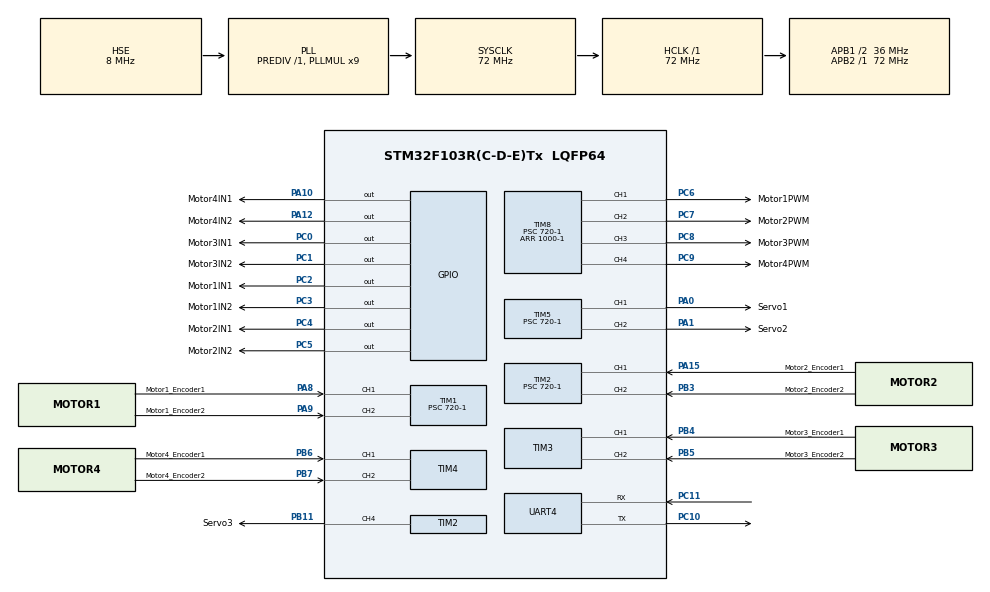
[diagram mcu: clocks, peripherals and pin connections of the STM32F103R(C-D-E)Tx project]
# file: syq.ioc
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Mcu.Family=STM32F1
Mcu.Name=STM32F103R(C-D-E)Tx
Mcu.Package=LQFP64
NVIC.PriorityGroup=NVIC_PRIORITYGROUP_4
NVIC.TIM8_UP_IRQn=true\:0\:0\:false\:false\:true\:true\:true\:true
PA0-WKUP.GPIO_Label=Servo1
PA0-WKUP.Signal=S_TIM5_CH1
PA1.GPIO_Label=Servo2
PA1.Signal=S_TIM5_CH2
PA10.GPIO_Label=Motor4IN1
PA10.Signal=GPIO_Output
PA12.GPIO_Label=Motor4IN2
PA12.Signal=GPIO_Output
PA13.Mode=Serial_Wire
PA13.Signal=SYS_JTMS-SWDIO
PA14.Mode=Serial_Wire
PA14.Signal=SYS_JTCK-SWCLK
PA15.GPIO_Label=Motor2_Encoder1
PA15.Signal=S_TIM2_CH1_ETR
PA8.GPIO_Label=Motor1_Encoder1
PA8.Signal=S_TIM1_CH1
PA9.GPIO_Label=Motor1_Encoder2
PA9.Signal=S_TIM1_CH2
PB11.GPIO_Label=Servo3
PB11.Signal=S_TIM2_CH4
PB3.GPIO_Label=Motor2_Encoder2
PB3.Signal=S_TIM2_CH2
PB4.GPIO_Label=Motor3_Encoder1
PB4.Signal=S_TIM3_CH1
PB5.GPIO_Label=Motor3_Encoder2
PB5.Signal=S_TIM3_CH2
PB6.GPIO_Label=Motor4_Encoder1
PB6.Signal=S_TIM4_CH1
PB7.GPIO_Label=Motor4_Encoder2
PB7.Signal=S_TIM4_CH2
PC0.GPIO_Label=Motor3IN1
PC0.Signal=GPIO_Output
PC1.GPIO_Label=Motor3IN2
PC1.Signal=GPIO_Output
PC10.Mode=Asynchronous
PC10.Signal=UART4_TX
PC11.Mode=Asynchronous
PC11.Signal=UART4_RX
PC2.GPIO_Label=Motor1IN1
PC2.Signal=GPIO_Output
PC3.GPIO_Label=Motor1IN2
PC3.Signal=GPIO_Output
PC4.GPIO_Label=Motor2IN1
PC4.Signal=GPIO_Output
PC5.GPIO_Label=Motor2IN2
PC5.Signal=GPIO_Output
PC6.GPIO_Label=Motor1PWM
PC6.Signal=S_TIM8_CH1
PC7.GPIO_Label=Motor2PWM
PC7.Signal=S_TIM8_CH2
PC8.GPIO_Label=Motor3PWM
PC8.Signal=S_TIM8_CH3
PC9.GPIO_Label=Motor4PWM
PC9.Signal=S_TIM8_CH4
PD0-OSC_IN.Mode=HSE-External-Oscillator
PD0-OSC_IN.Signal=RCC_OSC_IN
PD1-OSC_OUT.Mode=HSE-External-Oscillator
PD1-OSC_OUT.Signal=RCC_OSC_OUT
ProjectManager.HeapSize=0x200
ProjectManager.StackSize=0x400
ProjectManager.TargetToolchain=MDK-ARM V5.32
RCC.AHBFreq_Value=72000000
RCC.APB1CLKDivider=RCC_HCLK_DIV2
RCC.APB1Freq_Value=36000000
RCC.APB1TimFreq_Value=72000000
RCC.APB2Freq_Value=72000000
RCC.APB2TimFreq_Value=72000000
RCC.HCLKFreq_Value=72000000
RCC.PLLMUL=RCC_PLL_MUL9
RCC.PLLSourceVirtual=RCC_PLLSOURCE_HSE
RCC.SYSCLKFreq_VALUE=72000000
RCC.SYSCLKSource=RCC_SYSCLKSOURCE_PLLCLK
RCC.USBFreq_Value=72000000
SH.S_TIM1_CH1.0=TIM1_CH1,Encoder_Interface
SH.S_TIM1_CH2.0=TIM1_CH2,Encoder_Interface
SH.S_TIM2_CH1_ETR.0=TIM2_CH1,Encoder_Interface
SH.S_TIM2_CH2.0=TIM2_CH2,Encoder_Interface
SH.S_TIM2_CH4.0=TIM2_CH4,PWM Generation4 CH4
SH.S_TIM3_CH1.0=TIM3_CH1,Encoder_Interface
SH.S_TIM3_CH2.0=TIM3_CH2,Encoder_Interface
SH.S_TIM4_CH1.0=TIM4_CH1,Encoder_Interface
SH.S_TIM4_CH2.0=TIM4_CH2,Encoder_Interface
SH.S_TIM5_CH1.0=TIM5_CH1,PWM Generation1 CH1
SH.S_TIM5_CH2.0=TIM5_CH2,PWM Generation2 CH2
SH.S_TIM8_CH1.0=TIM8_CH1,PWM Generation1 CH1
SH.S_TIM8_CH2.0=TIM8_CH2,PWM Generation2 CH2
SH.S_TIM8_CH3.0=TIM8_CH3,PWM Generation3 CH3
SH.S_TIM8_CH4.0=TIM8_CH4,PWM Generation4 CH4
TIM1.EncoderMode=TIM_ENCODERMODE_TI12
TIM1.IC1Filter=15
TIM1.IC2Filter=15
TIM1.Period=100-1
TIM1.Prescaler=720-1
TIM2.Channel-PWM\ Generation4\ CH4=TIM_CHANNEL_4
TIM2.EncoderMode=TIM_ENCODERMODE_TI12
TIM2.Period=2000-1
TIM2.Prescaler=720-1
TIM3.EncoderMode=TIM_ENCODERMODE_TI12
TIM4.EncoderMode=TIM_ENCODERMODE_TI12
TIM5.Channel-PWM\ Generation1\ CH1=TIM_CHANNEL_1
TIM5.Channel-PWM\ Generation2\ CH2=TIM_CHANNEL_2
TIM5.Period=2000-1
TIM5.Prescaler=720-1
TIM8.Channel-PWM\ Generation1\ CH1=TIM_CHANNEL_1
TIM8.Channel-PWM\ Generation2\ CH2=TIM_CHANNEL_2
TIM8.Channel-PWM\ Generation3\ CH3=TIM_CHANNEL_3
TIM8.Channel-PWM\ Generation4\ CH4=TIM_CHANNEL_4
TIM8.Period=1000-1
TIM8.Prescaler=720-1
UART4.VirtualMode=Asynchronous
VP_TIM5_VS_ClockSourceINT.Mode=Internal
board=custom

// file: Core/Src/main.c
/* USER CODE BEGIN Header */
/**
  ******************************************************************************
  * @file           : main.c
  * @brief          : Main program body
  ******************************************************************************
  * @attention
  *
  * Copyright (c) 2025 STMicroelectronics.
  * All rights reserved.
  *
  * This software is licensed under terms that can be found in the LICENSE file
  * in the root directory of this software component.
  * If no LICENSE file comes with this software, it is provided AS-IS.
  *
  ******************************************************************************
  */
/* USER CODE END Header */
#include "main.h"
#include "tim.h"
#include "usart.h"
#include "gpio.h"

void SystemClock_Config(void);

int main(void)
{

  /* MCU Configuration--------------------------------------------------------*/

  /* Reset of all peripherals, Initializes the Flash interface and the Systick. */
  HAL_Init();

  /* Configure the system clock */
  SystemClock_Config();

  /* Initialize all configured peripherals */
  MX_GPIO_Init();
  MX_TIM1_Init();
  MX_TIM2_Init();
  MX_TIM3_Init();
  MX_TIM4_Init();
  MX_TIM8_Init();
  MX_TIM5_Init();
  MX_UART4_Init();
  /* USER CODE BEGIN 2 */
	HAL_TIM_Encoder_Start(&htim1,TIM_CHANNEL_ALL);
	HAL_TIM_Encoder_Start(&htim2,TIM_CHANNEL_ALL);
	HAL_TIM_Encoder_Start(&htim3,TIM_CHANNEL_ALL);
	HAL_TIM_Encoder_Start(&htim4,TIM_CHANNEL_ALL);
	HAL_TIM_PWM_Start(&htim2,TIM_CHANNEL_4);
	HAL_TIM_PWM_Start(&htim5,TIM_CHANNEL_1);
	HAL_TIM_PWM_Start(&htim5,TIM_CHANNEL_2);
	HAL_TIM_PWM_Start(&htim8,TIM_CHANNEL_1);
	HAL_TIM_PWM_Start(&htim8,TIM_CHANNEL_2);
	HAL_TIM_PWM_Start(&htim8,TIM_CHANNEL_3);
	HAL_TIM_PWM_Start(&htim8,TIM_CHANNEL_4);
	HAL_TIM_Base_Start_IT(&htim8);
  /* USER CODE END 2 */

  /* Infinite loop */
  while (1)
  {

  }
}

void SystemClock_Config(void)
{
  RCC_OscInitTypeDef RCC_OscInitStruct = {0};
  RCC_ClkInitTypeDef RCC_ClkInitStruct = {0};

  /** Initializes the RCC Oscillators according to the specified parameters
  * in the RCC_OscInitTypeDef structure.
  */
  RCC_OscInitStruct.OscillatorType = RCC_OSCILLATORTYPE_HSE;
  RCC_OscInitStruct.HSEState = RCC_HSE_ON;
  RCC_OscInitStruct.HSEPredivValue = RCC_HSE_PREDIV_DIV1;
  RCC_OscInitStruct.HSIState = RCC_HSI_ON;
  RCC_OscInitStruct.PLL.PLLState = RCC_PLL_ON;
  RCC_OscInitStruct.PLL.PLLSource = RCC_PLLSOURCE_HSE;
  RCC_OscInitStruct.PLL.PLLMUL = RCC_PLL_MUL9;
  if (HAL_RCC_OscConfig(&RCC_OscInitStruct) != HAL_OK)
  {
    Error_Handler();
  }

  /** Initializes the CPU, AHB and APB buses clocks
  */
  RCC_ClkInitStruct.ClockType = RCC_CLOCKTYPE_HCLK|RCC_CLOCKTYPE_SYSCLK
                              |RCC_CLOCKTYPE_PCLK1|RCC_CLOCKTYPE_PCLK2;
  RCC_ClkInitStruct.SYSCLKSource = RCC_SYSCLKSOURCE_PLLCLK;
  RCC_ClkInitStruct.AHBCLKDivider = RCC_SYSCLK_DIV1;
  RCC_ClkInitStruct.APB1CLKDivider = RCC_HCLK_DIV2;
  RCC_ClkInitStruct.APB2CLKDivider = RCC_HCLK_DIV1;

  if (HAL_RCC_ClockConfig(&RCC_ClkInitStruct, FLASH_LATENCY_2) != HAL_OK)
  {
    Error_Handler();
  }
}

void Error_Handler(void)
{
  __disable_irq();
  while (1)
  {
  }
}
